# EZR32HG220F32R60 register map
File version: 5.8.2
CPU: CM0PLUS r0p1, little endian, no MPU, no FPU, 3 interrupt priority bits
Registers are 32-bit, read-write, reset 0x0 unless marked. A register's access mark holds for its fields unless they carry their own. Offsets are from the block's base; [hi:lo] are bit positions.

## MSC
Base 0x400C0000
0x00 CTRL reset 0x1 — Memory System Control Register
  [0] BUSFAULT — Bus Fault Response Enable
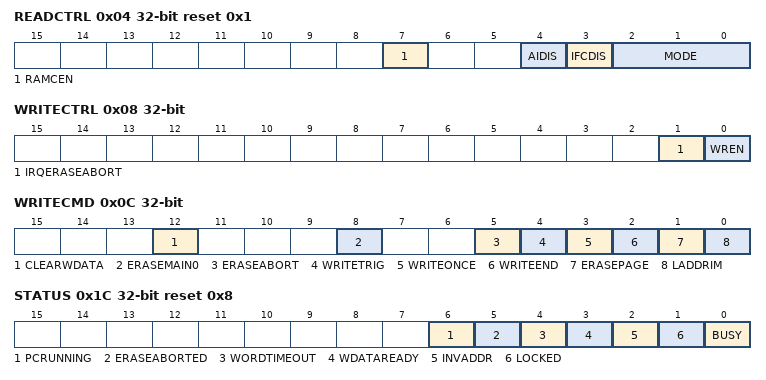
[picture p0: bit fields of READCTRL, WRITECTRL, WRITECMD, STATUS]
0x04 READCTRL reset 0x1 — Read Control Register
  [7] RAMCEN — RAM Cache Enable
  [4] AIDIS — Automatic Invalidate Disable
  [3] IFCDIS — Internal Flash Cache Disable
  [2:0] MODE — Read Mode
    0=WS0 (Zero wait-states inserted in fetch or read transfers.); 1=WS1 (One wait-state inserted for each fetch or read transfer. This mode is required for a core frequency above 16 MHz.)
0x08 WRITECTRL — Write Control Register
  [1] IRQERASEABORT — Abort Page Erase on Interrupt
  [0] WREN — Enable Write/Erase Controller
0x0C WRITECMD wo — Write Command Register
  [12] CLEARWDATA — Clear WDATA state
  [8] ERASEMAIN0 — Mass erase region 0
  [5] ERASEABORT — Abort erase sequence
  [4] WRITETRIG — Word Write Sequence Trigger
  [3] WRITEONCE — Word Write-Once Trigger
  [2] WRITEEND — End Write Mode
  [1] ERASEPAGE
  [0] LADDRIM — Load MSC_ADDRB into ADDR
0x10 ADDRB — Page Erase/Write Address Buffer
  [31:0] ADDRB — Page Erase or Write Address Buffer
0x18 WDATA — Write Data Register
  [31:0] WDATA — Write Data
0x1C STATUS ro reset 0x8
  [6] PCRUNNING — Performance Counters Running
  [5] ERASEABORTED — The Current Flash Erase Operation Aborted
  [4] WORDTIMEOUT — Flash Write Word Timeout
  [3] WDATAREADY — WDATA Write Ready
  [2] INVADDR — Invalid Write Address or Erase Page
  [1] LOCKED — Access Locked
  [0] BUSY — Erase/Write Busy
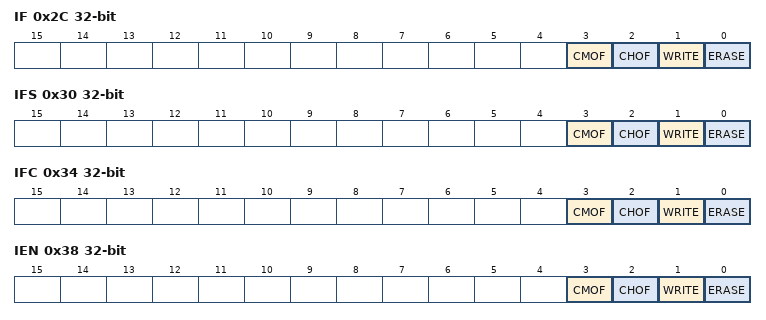
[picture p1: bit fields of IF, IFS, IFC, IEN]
0x2C IF ro — Interrupt Flag Register
  [3] CMOF — Cache Misses Overflow Interrupt Flag
  [2] CHOF — Cache Hits Overflow Interrupt Flag
  [1] WRITE — Write Done Interrupt Read Flag
  [0] ERASE — Erase Done Interrupt Read Flag
0x30 IFS wo — Interrupt Flag Set Register
  [3] CMOF — Cache Misses Overflow Interrupt Set
  [2] CHOF — Cache Hits Overflow Interrupt Set
  [1] WRITE — Write Done Interrupt Set
  [0] ERASE — Erase Done Interrupt Set
0x34 IFC wo — Interrupt Flag Clear Register
  [3] CMOF — Cache Misses Overflow Interrupt Clear
  [2] CHOF — Cache Hits Overflow Interrupt Clear
  [1] WRITE — Write Done Interrupt Clear
  [0] ERASE — Erase Done Interrupt Clear
0x38 IEN — Interrupt Enable Register
  [3] CMOF — Cache Misses Overflow Interrupt Enable
  [2] CHOF — Cache Hits Overflow Interrupt Enable
  [1] WRITE — Write Done Interrupt Enable
  [0] ERASE — Erase Done Interrupt Enable
0x3C LOCK — Configuration Lock Register
  [15:0] LOCKKEY — Configuration Lock
    0=UNLOCKED; 1=LOCKED
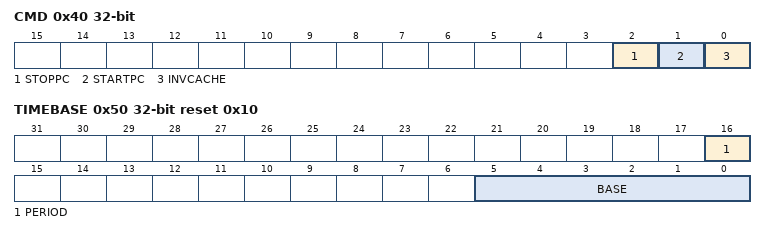
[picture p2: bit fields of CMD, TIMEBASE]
0x40 CMD wo — Command Register
  [2] STOPPC — Stop Performance Counters
  [1] STARTPC — Start Performance Counters
  [0] INVCACHE — Invalidate Instruction Cache
0x44 CACHEHITS ro — Cache Hits Performance Counter
  [19:0] CACHEHITS — Cache hits since last performance counter start command.
0x48 CACHEMISSES ro — Cache Misses Performance Counter
  [19:0] CACHEMISSES — Cache misses since last performance counter start command.
0x50 TIMEBASE reset 0x10 — Flash Write and Erase Timebase
  [16] PERIOD — Sets the timebase period
  [5:0] BASE — Timebase used by MSC to time flash writes and erases
0x54 MASSLOCK reset 0x1 — Mass Erase Lock Register
  [15:0] LOCKKEY — Mass Erase Lock
    0=UNLOCKED (Mass erase unlocked.); 1=LOCKED (Mass erase locked.)
0x58 IRQLATENCY
  [7:0] IRQLATENCY

## EMU
Base 0x400C6000
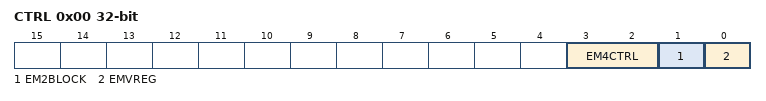
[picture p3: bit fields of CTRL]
0x00 CTRL — Control Register
  [3:2] EM4CTRL — Energy Mode 4 Control
  [1] EM2BLOCK — Energy Mode 2 Block
  [0] EMVREG — Energy Mode Voltage Regulator Control
0x08 LOCK — Configuration Lock Register
  [15:0] LOCKKEY — Configuration Lock Key
    0=UNLOCKED; 1=LOCKED
0x24 AUXCTRL — Auxiliary Control Register
  [0] HRCCLR — Hard Reset Cause Clear

## RMU
Base 0x400CA000
0x00 CTRL — Control Register
  [0] LOCKUPRDIS — Lockup Reset Disable
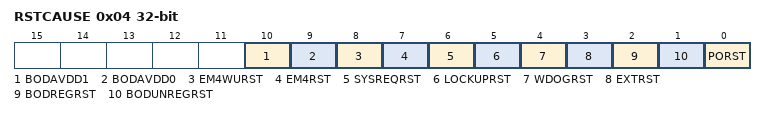
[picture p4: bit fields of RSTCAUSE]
0x04 RSTCAUSE ro — Reset Cause Register
  [10] BODAVDD1 — AVDD1 Bod Reset
  [9] BODAVDD0 — AVDD0 Bod Reset
  [8] EM4WURST — EM4 Wake-up Reset
  [7] EM4RST — EM4 Reset
  [6] SYSREQRST — System Request Reset
  [5] LOCKUPRST — LOCKUP Reset
  [4] WDOGRST — Watchdog Reset
  [3] EXTRST — External Pin Reset
  [2] BODREGRST — Brown Out Detector Regulated Domain Reset
  [1] BODUNREGRST — Brown Out Detector Unregulated Domain Reset
  [0] PORST — Power On Reset
0x08 CMD wo — Command Register
  [0] RCCLR — Reset Cause Clear

## Notices in the file
# License
Copyright 2019 Silicon Laboratories Inc. www.silabs.com
SPDX-License-Identifier: Zlib
The licensor of this software is Silicon Laboratories Inc.
This software is provided 'as-is', without any express or implied
warranty. In no event will the authors be held liable for any damages
arising from the use of this software.
Permission is granted to anyone to use this software for any purpose,
including commercial applications, and to alter it and redistribute it
freely, subject to the following restrictions:
1. The origin of this software must not be misrepresented; you must not
claim that you wrote the original software. If you use this software
in a product, an acknowledgment in the product documentation would be
appreciated but is not required.
2. Altered source versions must be plainly marked as such, and must not be
misrepresented as being the original software.
3. This notice may not be removed or altered from any source distribution.
